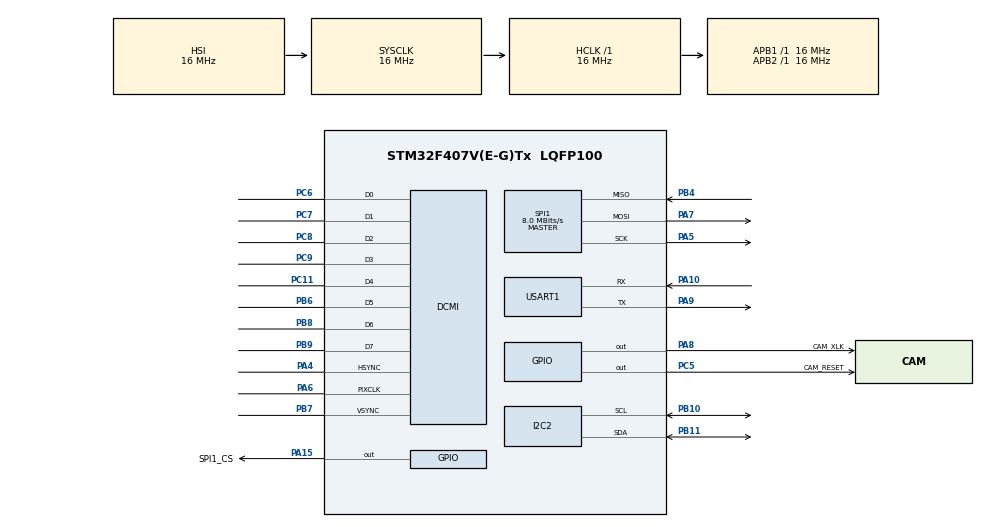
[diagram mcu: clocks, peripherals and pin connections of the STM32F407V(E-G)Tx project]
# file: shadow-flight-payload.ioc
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FREERTOS.Tasks01=defaultTask,0,128,StartDefaultTask,Default,NULL,Dynamic,NULL,NULL
Mcu.Family=STM32F4
Mcu.Name=STM32F407V(E-G)Tx
Mcu.Package=LQFP100
NVIC.PriorityGroup=NVIC_PRIORITYGROUP_4
PA10.Mode=Asynchronous
PA10.Signal=USART1_RX
PA13.Mode=Serial_Wire
PA13.Signal=SYS_JTMS-SWDIO
PA14.Mode=Serial_Wire
PA14.Signal=SYS_JTCK-SWCLK
PA15.GPIO_Label=SPI1_CS
PA15.Signal=GPIO_Output
PA4.Mode=Slave_8_bits_External_Synchro
PA4.Signal=DCMI_HSYNC
PA5.Mode=Full_Duplex_Master
PA5.Signal=SPI1_SCK
PA6.Mode=Slave_8_bits_External_Synchro
PA6.Signal=DCMI_PIXCLK
PA7.Mode=Full_Duplex_Master
PA7.Signal=SPI1_MOSI
PA8.GPIO_Label=CAM_XLK
PA8.Signal=GPIO_Output
PA9.Mode=Asynchronous
PA9.Signal=USART1_TX
PB10.Mode=I2C
PB10.Signal=I2C2_SCL
PB11.Mode=I2C
PB11.Signal=I2C2_SDA
PB4.Mode=Full_Duplex_Master
PB4.Signal=SPI1_MISO
PB6.Mode=Slave_8_bits_External_Synchro
PB6.Signal=DCMI_D5
PB7.Mode=Slave_8_bits_External_Synchro
PB7.Signal=DCMI_VSYNC
PB8.Mode=Slave_8_bits_External_Synchro
PB8.Signal=DCMI_D6
PB9.Mode=Slave_8_bits_External_Synchro
PB9.Signal=DCMI_D7
PC11.Mode=Slave_8_bits_External_Synchro
PC11.Signal=DCMI_D4
PC14-OSC32_IN.Mode=LSE-External-Oscillator
PC14-OSC32_IN.Signal=RCC_OSC32_IN
PC15-OSC32_OUT.Mode=LSE-External-Oscillator
PC15-OSC32_OUT.Signal=RCC_OSC32_OUT
PC5.GPIO_Label=CAM_RESET
PC5.Signal=GPIO_Output
PC6.Mode=Slave_8_bits_External_Synchro
PC6.Signal=DCMI_D0
PC7.Mode=Slave_8_bits_External_Synchro
PC7.Signal=DCMI_D1
PC8.Mode=Slave_8_bits_External_Synchro
PC8.Signal=DCMI_D2
PC9.Mode=Slave_8_bits_External_Synchro
PC9.Signal=DCMI_D3
PH0-OSC_IN.Mode=HSE-External-Oscillator
PH0-OSC_IN.Signal=RCC_OSC_IN
PH1-OSC_OUT.Mode=HSE-External-Oscillator
PH1-OSC_OUT.Signal=RCC_OSC_OUT
ProjectManager.HeapSize=0x200
ProjectManager.StackSize=0x400
ProjectManager.TargetToolchain=STM32CubeIDE
RCC.AHBFreq_Value=16000000
RCC.APB1Freq_Value=16000000
RCC.APB2Freq_Value=16000000
RCC.CortexFreq_Value=16000000
RCC.HSE_VALUE=25000000
RCC.HSI_VALUE=16000000
RCC.SYSCLKFreq_VALUE=16000000
RCC.VCOOutputFreq_Value=192000000
SPI1.CalculateBaudRate=8.0 MBits/s
SPI1.Direction=SPI_DIRECTION_2LINES
SPI1.Mode=SPI_MODE_MASTER
SPI1.VirtualType=VM_MASTER
USART1.VirtualMode=VM_ASYNC
VP_FREERTOS_VS_CMSIS_V1.Mode=CMSIS_V1
board=custom

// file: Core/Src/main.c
/* USER CODE BEGIN Header */
/**
  ******************************************************************************
  * @file           : main.c
  * @brief          : Main program body
  ******************************************************************************
  * @attention
  *
  * Copyright (c) 2025 STMicroelectronics.
  * All rights reserved.
  *
  * This software is licensed under terms that can be found in the LICENSE file
  * in the root directory of this software component.
  * If no LICENSE file comes with this software, it is provided AS-IS.
  *
  ******************************************************************************
  */
/* USER CODE END Header */
#include "main.h"
#include "cmsis_os.h"

/* USER CODE BEGIN Includes */
#include "stdio.h"
#include "string.h"

/* USER CODE END Includes */

DCMI_HandleTypeDef hdcmi;

I2C_HandleTypeDef hi2c2;

SPI_HandleTypeDef hspi1;

UART_HandleTypeDef huart1;

osThreadId defaultTaskHandle;

void SystemClock_Config(void);
static void MX_GPIO_Init(void);
static void MX_USART1_UART_Init(void);
static void MX_DCMI_Init(void);
static void MX_I2C2_Init(void);
static void MX_SPI1_Init(void);
void StartDefaultTask(void const * argument);

/* USER CODE BEGIN 0 */
#define BUFFER_SIZE 1024

char buffer[BUFFER_SIZE] = {0};

/* USER CODE END 0 */

int main(void)
{

  /* MCU Configuration--------------------------------------------------------*/

  /* Reset of all peripherals, Initializes the Flash interface and the Systick. */
  HAL_Init();

  /* Configure the system clock */
  SystemClock_Config();

  /* Initialize all configured peripherals */
  MX_GPIO_Init();
  MX_USART1_UART_Init();
  MX_DCMI_Init();
  MX_I2C2_Init();
  MX_SPI1_Init();
  /* USER CODE BEGIN 2 */
  int len = snprintf(buffer, sizeof(buffer), "%s\r\n", "HELLO STM32");

  /* check for overflow */
  if(len >= sizeof(buffer)) {
	  /*todo: handle overflow*/
  }

  /* USER CODE END 2 */

  /* Create the thread(s) */
  /* definition and creation of defaultTask */
  osThreadDef(defaultTask, StartDefaultTask, osPriorityNormal, 0, 128);
  defaultTaskHandle = osThreadCreate(osThread(defaultTask), NULL);

  /* Start scheduler */
  osKernelStart();

  /* We should never get here as control is now taken by the scheduler */

  /* Infinite loop */
  while (1)
  {

    /* USER CODE BEGIN 3 */
	  HAL_UART_Transmit(&huart1, (uint8_t*)buffer, strlen(buffer), 1000);
	  HAL_Delay(500);
  }
  /* USER CODE END 3 */
}

void SystemClock_Config(void)
{
  RCC_OscInitTypeDef RCC_OscInitStruct = {0};
  RCC_ClkInitTypeDef RCC_ClkInitStruct = {0};

  /** Configure the main internal regulator output voltage
  */
  __HAL_RCC_PWR_CLK_ENABLE();
  __HAL_PWR_VOLTAGESCALING_CONFIG(PWR_REGULATOR_VOLTAGE_SCALE1);

  /** Initializes the RCC Oscillators according to the specified parameters
  * in the RCC_OscInitTypeDef structure.
  */
  RCC_OscInitStruct.OscillatorType = RCC_OSCILLATORTYPE_HSI;
  RCC_OscInitStruct.HSIState = RCC_HSI_ON;
  RCC_OscInitStruct.HSICalibrationValue = RCC_HSICALIBRATION_DEFAULT;
  RCC_OscInitStruct.PLL.PLLState = RCC_PLL_NONE;
  if (HAL_RCC_OscConfig(&RCC_OscInitStruct) != HAL_OK)
  {
    Error_Handler();
  }

  /** Initializes the CPU, AHB and APB buses clocks
  */
  RCC_ClkInitStruct.ClockType = RCC_CLOCKTYPE_HCLK|RCC_CLOCKTYPE_SYSCLK
                              |RCC_CLOCKTYPE_PCLK1|RCC_CLOCKTYPE_PCLK2;
  RCC_ClkInitStruct.SYSCLKSource = RCC_SYSCLKSOURCE_HSI;
  RCC_ClkInitStruct.AHBCLKDivider = RCC_SYSCLK_DIV1;
  RCC_ClkInitStruct.APB1CLKDivider = RCC_HCLK_DIV1;
  RCC_ClkInitStruct.APB2CLKDivider = RCC_HCLK_DIV1;

  if (HAL_RCC_ClockConfig(&RCC_ClkInitStruct, FLASH_LATENCY_0) != HAL_OK)
  {
    Error_Handler();
  }
}

static void MX_DCMI_Init(void)
{

  hdcmi.Instance = DCMI;
  hdcmi.Init.SynchroMode = DCMI_SYNCHRO_HARDWARE;
  hdcmi.Init.PCKPolarity = DCMI_PCKPOLARITY_FALLING;
  hdcmi.Init.VSPolarity = DCMI_VSPOLARITY_LOW;
  hdcmi.Init.HSPolarity = DCMI_HSPOLARITY_LOW;
  hdcmi.Init.CaptureRate = DCMI_CR_ALL_FRAME;
  hdcmi.Init.ExtendedDataMode = DCMI_EXTEND_DATA_8B;
  hdcmi.Init.JPEGMode = DCMI_JPEG_DISABLE;
  if (HAL_DCMI_Init(&hdcmi) != HAL_OK)
  {
    Error_Handler();
  }

}

static void MX_I2C2_Init(void)
{

  hi2c2.Instance = I2C2;
  hi2c2.Init.ClockSpeed = 100000;
  hi2c2.Init.DutyCycle = I2C_DUTYCYCLE_2;
  hi2c2.Init.OwnAddress1 = 0;
  hi2c2.Init.AddressingMode = I2C_ADDRESSINGMODE_7BIT;
  hi2c2.Init.DualAddressMode = I2C_DUALADDRESS_DISABLE;
  hi2c2.Init.OwnAddress2 = 0;
  hi2c2.Init.GeneralCallMode = I2C_GENERALCALL_DISABLE;
  hi2c2.Init.NoStretchMode = I2C_NOSTRETCH_DISABLE;
  if (HAL_I2C_Init(&hi2c2) != HAL_OK)
  {
    Error_Handler();
  }

}

static void MX_SPI1_Init(void)
{

  /* SPI1 parameter configuration*/
  hspi1.Instance = SPI1;
  hspi1.Init.Mode = SPI_MODE_MASTER;
  hspi1.Init.Direction = SPI_DIRECTION_2LINES;
  hspi1.Init.DataSize = SPI_DATASIZE_8BIT;
  hspi1.Init.CLKPolarity = SPI_POLARITY_LOW;
  hspi1.Init.CLKPhase = SPI_PHASE_1EDGE;
  hspi1.Init.NSS = SPI_NSS_SOFT;
  hspi1.Init.BaudRatePrescaler = SPI_BAUDRATEPRESCALER_2;
  hspi1.Init.FirstBit = SPI_FIRSTBIT_MSB;
  hspi1.Init.TIMode = SPI_TIMODE_DISABLE;
  hspi1.Init.CRCCalculation = SPI_CRCCALCULATION_DISABLE;
  hspi1.Init.CRCPolynomial = 10;
  if (HAL_SPI_Init(&hspi1) != HAL_OK)
  {
    Error_Handler();
  }

}

static void MX_USART1_UART_Init(void)
{

  huart1.Instance = USART1;
  huart1.Init.BaudRate = 115200;
  huart1.Init.WordLength = UART_WORDLENGTH_8B;
  huart1.Init.StopBits = UART_STOPBITS_1;
  huart1.Init.Parity = UART_PARITY_NONE;
  huart1.Init.Mode = UART_MODE_TX_RX;
  huart1.Init.HwFlowCtl = UART_HWCONTROL_NONE;
  huart1.Init.OverSampling = UART_OVERSAMPLING_16;
  if (HAL_UART_Init(&huart1) != HAL_OK)
  {
    Error_Handler();
  }

}

static void MX_GPIO_Init(void)
{
  GPIO_InitTypeDef GPIO_InitStruct = {0};

  /* GPIO Ports Clock Enable */
  __HAL_RCC_GPIOC_CLK_ENABLE();
  __HAL_RCC_GPIOH_CLK_ENABLE();
  __HAL_RCC_GPIOA_CLK_ENABLE();
  __HAL_RCC_GPIOB_CLK_ENABLE();

  /*Configure GPIO pin Output Level */
  HAL_GPIO_WritePin(CAM_RESET_GPIO_Port, CAM_RESET_Pin, GPIO_PIN_RESET);

  /*Configure GPIO pin Output Level */
  HAL_GPIO_WritePin(GPIOA, CAM_XLK_Pin|SPI1_CS_Pin, GPIO_PIN_RESET);

  /*Configure GPIO pin : CAM_RESET_Pin */
  GPIO_InitStruct.Pin = CAM_RESET_Pin;
  GPIO_InitStruct.Mode = GPIO_MODE_OUTPUT_PP;
  GPIO_InitStruct.Pull = GPIO_NOPULL;
  GPIO_InitStruct.Speed = GPIO_SPEED_FREQ_LOW;
  HAL_GPIO_Init(CAM_RESET_GPIO_Port, &GPIO_InitStruct);

  /*Configure GPIO pins : CAM_XLK_Pin SPI1_CS_Pin */
  GPIO_InitStruct.Pin = CAM_XLK_Pin|SPI1_CS_Pin;
  GPIO_InitStruct.Mode = GPIO_MODE_OUTPUT_PP;
  GPIO_InitStruct.Pull = GPIO_NOPULL;
  GPIO_InitStruct.Speed = GPIO_SPEED_FREQ_LOW;
  HAL_GPIO_Init(GPIOA, &GPIO_InitStruct);

}

void StartDefaultTask(void const * argument)
{
  for(;;)
  {
    osDelay(1);
  }
}

void Error_Handler(void)
{
  __disable_irq();
  while (1)
  {
  }
}

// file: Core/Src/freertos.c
/* USER CODE BEGIN Header */
/**
  ******************************************************************************
  * File Name          : freertos.c
  * Description        : Code for freertos applications
  ******************************************************************************
  * @attention
  *
  * Copyright (c) 2026 STMicroelectronics.
  * All rights reserved.
  *
  * This software is licensed under terms that can be found in the LICENSE file
  * in the root directory of this software component.
  * If no LICENSE file comes with this software, it is provided AS-IS.
  *
  ******************************************************************************
  */
/* USER CODE END Header */

#include "FreeRTOS.h"
#include "task.h"
#include "main.h"

/* GetIdleTaskMemory prototype (linked to static allocation support) */
void vApplicationGetIdleTaskMemory( StaticTask_t **ppxIdleTaskTCBBuffer, StackType_t **ppxIdleTaskStackBuffer, uint32_t *pulIdleTaskStackSize );

/* USER CODE BEGIN GET_IDLE_TASK_MEMORY */
static StaticTask_t xIdleTaskTCBBuffer;
static StackType_t xIdleStack[configMINIMAL_STACK_SIZE];

void vApplicationGetIdleTaskMemory( StaticTask_t **ppxIdleTaskTCBBuffer, StackType_t **ppxIdleTaskStackBuffer, uint32_t *pulIdleTaskStackSize )
{
  *ppxIdleTaskTCBBuffer = &xIdleTaskTCBBuffer;
  *ppxIdleTaskStackBuffer = &xIdleStack[0];
  *pulIdleTaskStackSize = configMINIMAL_STACK_SIZE;
  /* place for user code */
}
/* USER CODE END GET_IDLE_TASK_MEMORY */
